# AC33GA256 register map
Vendor: ABOV Semiconductor Co., Ltd.; File version: 0.1
ARM 32-bit Cortex-M3 Microcontroller based device.
CPU: CM3 r1p0, little endian, no MPU, no FPU, 3 interrupt priority bits
Registers are 32-bit, read-write, reset 0x0 unless marked. A register's access mark holds for its fields unless they carry their own. Offsets are from the block's base; lines under a group give offsets from that group; [hi:lo] are bit positions; {n}, {i} and the like mark numbered series; 'fields as' and 'values as' point back to an identical list; <NAME> marks a mode.

## Memory map
0x40000000 PMU size 0xE0 — POWER MANAGEMENT UNIT
0x400000E0 MEMCR size 0x20 — Memory Control Register
0x40000100 FMC size 0x100 — INTERNAL FLASH MEMORY
0x40000200 PCA size 0x20 — PORT MAP CONTROLLER
0x40000220 PCB size 0x20
0x40000240 PCC size 0x20
0x40000260 PCD size 0x20
0x40000280 PCE size 0x20
0x400002A0 PCF size 0x20
0x40000300 PA size 0x10 — GENERAL PURPOSE I/O
0x40000310 PB size 0x10
0x40000320 PC size 0x10
0x40000330 PD size 0x10
0x40000340 PE size 0x10
0x40000350 PF size 0x10
0x40000400 WDT size 0x100 — WATCH-DOG TIMER
0x40000500 FRT size 0x100 — Free-Run Timer
0x40000700 PWM0 size 0x1C — PWM Generator
0x40000720 PWM1 size 0x1C
0x40000740 PWM2 size 0x1C
0x40000760 PWM3 size 0x1C
0x4000077C PWMPRS0 size 0x4
0x40000780 PWM4 size 0x1C
0x400007A0 PWM5 size 0x1C
0x400007C0 PWM6 size 0x1C
0x400007E0 PWM7 size 0x1C
0x400007FC PWMPRS1 size 0x4
0x40000800 SPI0 size 0x20 — SERIAL PERIPHERAL INTERFACE
0x40000820 SPI1 size 0x20
0x40000A00 I2C0 size 0x80 — I2C Interface
0x40000A80 I2C1 size 0x80
0x40000B00 UART0 size 0x40 — UNIVERSAL ASYNCHRONOUS RECEIVER/TRANSMITTER
0x40000B40 UART1 size 0x40
0x40000B80 UART2 size 0x40
0x40000BC0 UART3 size 0x40
0x40000C00 T0 size 0x20 — 16-BIT TIMER
{0x40000C00+0x20*n} T{n} size 0x20 (n=1..9)
0x40000E00 ADC size 0x100 — 12-BIT A/D CONVERTER

## Interrupts
0 LVDDETECT (PMU)
1 SCLKFAIL (PMU)
2 XOSCFAIL (PMU)
3 WDT
4 FRT
{n+5} TIMER{n} (T{n}) (n=0..9)
16 GPIOA (PCA)
17 GPIOB (PCB)
18 GPIOC (PCC)
19 GPIOD (PCD)
20 GPIOE (PCE)
21 GPIOF (PCF)
{n+24} PWM{n} (n=0..7)
32 SPI0
33 SPI1
36 I2C0
37 I2C1
38 UART0
39 UART1
40 UART2
41 UART3
43 ADC

## PCA — PORT MAP CONTROLLER
Base 0x40000200
Same registers: PCB 0x40000220, PCC 0x40000240, PCD 0x40000260, PCE 0x40000280, PCF 0x400002A0
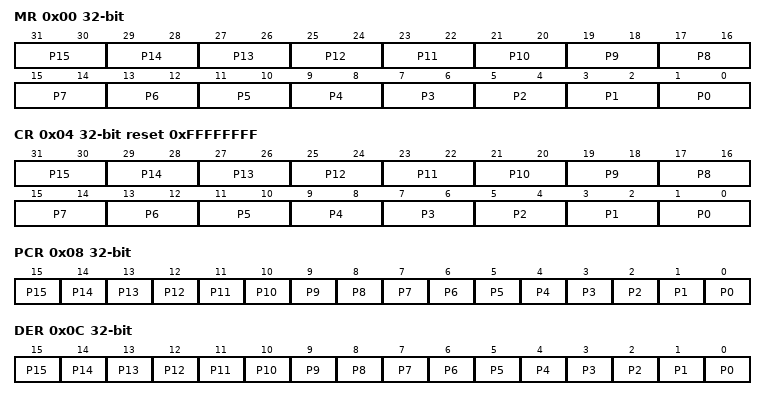
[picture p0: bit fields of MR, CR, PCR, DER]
0x00 MR — PORT x Pin MUX Register
  [31:30] P15 — P15 Pin Mux select
  [29:28] P14 — P14 MUX SEL
  [27:26] P13 — P13 Pin Mux select
  [25:24] P12 — P12 MUX SEL
  [23:22] P11 — P11 Pin Mux select
  [21:20] P10 — P10 MUX SEL
  [19:18] P9 — P9 Pin Mux select
  [17:16] P8 — P8 MUX SEL
  [15:14] P7 — P7 Pin Mux select
  [13:12] P6 — P6 MUX SEL
  [11:10] P5 — P5 Pin Mux select
  [9:8] P4 — P4 MUX SEL
  [7:6] P3 — P3 Pin Mux select
  [5:4] P2 — P2 MUX SEL
  [3:2] P1 — P1 Pin Mux select
  [1:0] P0 — P0 MUX SEL
0x04 CR reset 0xFFFFFFFF — PORT n Pin Control Register
  [31:30] P15 — P15 control select
  [29:28] P14 — P14 control SEL
  [27:26] P13 — P13 control select
  [25:24] P12 — P12 control SEL
  [23:22] P11 — P11 control select
  [21:20] P10 — P10 control SEL
  [19:18] P9 — P9 control select
  [17:16] P8 — P8 control SEL
  [15:14] P7 — P7 control select
  [13:12] P6 — P6 control SEL
  [11:10] P5 — P5 control select
  [9:8] P4 — P4 control SEL
  [7:6] P3 — P3 control select
  [5:4] P2 — P2 control SEL
  [3:2] P1 — P1 control select
  [1:0] P0 — P0 control SEL
0x08 PCR — PORT n Pull-up Resistor Control Register
  [n] P{n} (n=0..15) — P{n} pull-up enable
0x0C DER — PORT n Debounce Enable Register
  [n] P{n} (n=0..15) — P{n} Debounce enable
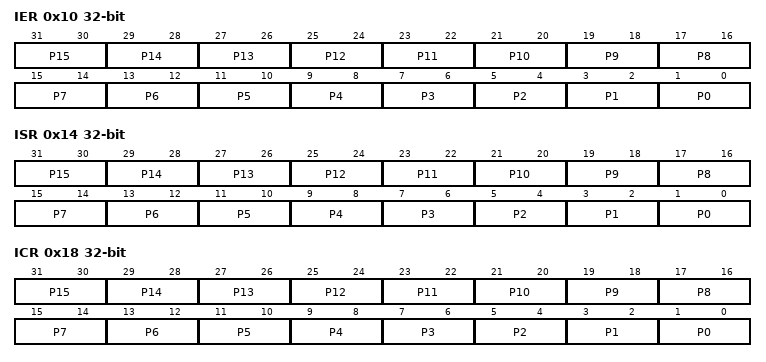
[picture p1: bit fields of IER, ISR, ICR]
0x10 IER — PORT n Interrupt Enable Register
  [31:30] P15 — P15 interrupt select
  [29:28] P14 — P14 interrupt SEL
  [27:26] P13 — P13 interrupt select
  [25:24] P12 — P12 interrupt SEL
  [23:22] P11 — P11 interrupt select
  [21:20] P10 — P10 interrupt SEL
  [19:18] P9 — P9 interrupt select
  [17:16] P8 — P8 interrupt SEL
  [15:14] P7 — P7 interrupt select
  [13:12] P6 — P6 interrupt SEL
  [11:10] P5 — P5 interrupt select
  [9:8] P4 — P4 interrupt SEL
  [7:6] P3 — P3 interrupt select
  [5:4] P2 — P2 interrupt SEL
  [3:2] P1 — P1 interrupt select
  [1:0] P0 — P0 interrupt enable
0x14 ISR — PORT n Interrupt Status Register
  [2n+1:2n] P{n} (n=0..15) — P{n} interrupt status
0x18 ICR — PORT n Interrupt Control Register
  [2n+1:2n] P{n} (n=0..15) — P{n} interrupt control
0x1C DPR — PORT n Debounce Prescaler Register
  [4:0] DPR — The debounce clock input divider

## Licence text in the file
THIS SOFTWARE IS PROVIDED "AS IS". NO WARRANTIES, WHETHER EXPRESS, IMPLIED. OR STATUTORY, INCLUDING, BUT NOT LIMITED TO, IMPLIED WARRANTIES OF. MERCHANTABILITY AND FITNESS FOR A PARTICULAR PURPOSE APPLY TO THIS SOFTWARE. ARM SHALL NOT, IN ANY CIRCUMSTANCES, BE LIABLE FOR SPECIAL, INCIDENTAL, OR. CONSEQUENTIAL DAMAGES, FOR ANY REASON WHATSOEVER.
